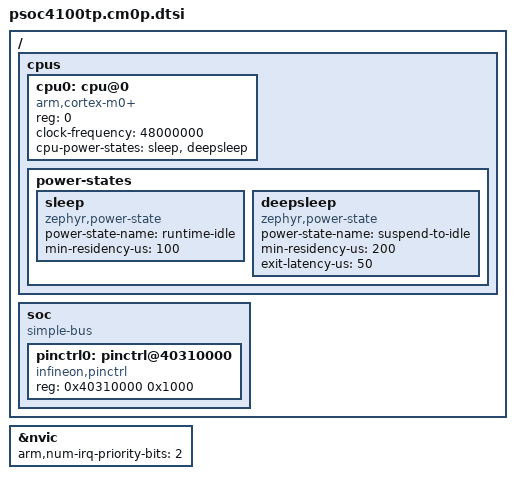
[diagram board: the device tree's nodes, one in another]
/*
 * SPDX-FileCopyrightText: <text>Copyright (c) 2026 Infineon Technologies AG,
 * or an affiliate of Infineon Technologies AG. All rights reserved.</text>
 *
 * SPDX-License-Identifier: Apache-2.0
 */

#include <arm/armv6-m.dtsi>

/ {
	cpus {
		#address-cells = <1>;
		#size-cells = <0>;

		cpu0: cpu@0 {
			device_type = "cpu";
			compatible = "arm,cortex-m0+";
			reg = <0>;
			clock-frequency = <48000000>;
			cpu-power-states = <&sleep &deepsleep>;
		};

		power-states {
			sleep: sleep {
				compatible = "zephyr,power-state";
				power-state-name = "runtime-idle";
				/* min-residency-us is set to 100 us safe margin
				 * to ensure sleep is only entered when the idle period is
				 * long enough to provide the power saving benefit.
				 */
				min-residency-us = <100>;
			};

			deepsleep: deepsleep {
				compatible = "zephyr,power-state";
				power-state-name = "suspend-to-idle";
				/* min-residency-us is set to 200 us safe margin
				 * to ensure deep-sleep is only entered when the idle period is
				 * long enough to provide the power saving benefit.
				 */
				min-residency-us = <200>;
				/*
				 * Worst-case latency to exit Deep Sleep. Must be at
				 * least one system tick. The PM core only arms the LPM
				 * companion WDT when this value rounds to >= 1 tick,
				 * but Deep Sleep is entered unconditionally.
				 */
				exit-latency-us = <50>;
			};
		};
	};

	soc {
		compatible = "simple-bus";
		#address-cells = <1>;
		#size-cells = <1>;
		ranges;

		/* Pinctrl node for Infineon PSOC4 SoC */
		pinctrl0: pinctrl@40310000 {
			compatible = "infineon,pinctrl";
			reg = <0x40310000 0x1000>;
			status = "okay";
		};
	};
};

&nvic {
	arm,num-irq-priority-bits = <2>;
};
